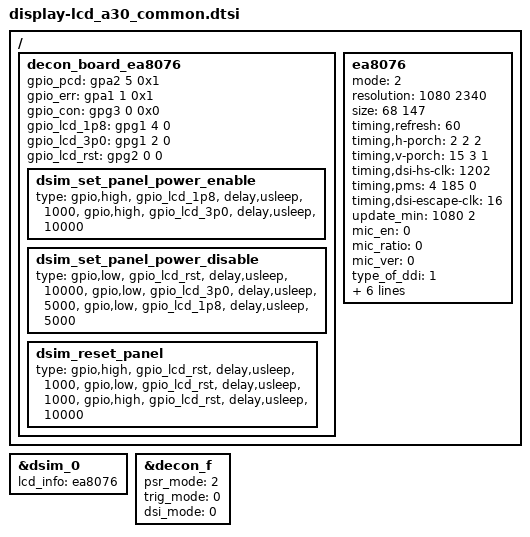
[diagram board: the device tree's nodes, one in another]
/*
 * SAMSUNG LCD Panel Device Tree Source
 *
 * Copyright (c) Samsung Electronics Co., Ltd.
 *		http://www.samsung.com
 *
 * This program is free software; you can redistribute it and/or modify
 * it under the terms of the GNU General Public License version 2 as
 * published by the Free Software Foundation.
 */

/ {
	fragment@lcd {
		target-path = "/";
		__overlay__ {
			decon_board_ea8076: decon_board_ea8076 {
				gpio_pcd = <&gpa2 5 0x1>;	/* EL_ON1_DET */
				gpio_err = <&gpa1 1 0x1>;	/* FG_ERR */
				gpio_con = <&gpg3 0 0x0>;	/* LCD_CON */

				gpio_lcd_1p8 = <&gpg1 4 0>;
				gpio_lcd_3p0 = <&gpg1 2 0>;
				gpio_lcd_rst = <&gpg2 0 0>;

				dsim_set_panel_power_enable {
					type =
					"gpio,high",	"gpio_lcd_1p8",
					"delay,usleep",	"1000",
					"gpio,high",	"gpio_lcd_3p0",
					"delay,usleep",	"10000";
				};
				dsim_set_panel_power_disable {
					type =
					"gpio,low",	"gpio_lcd_rst",
					"delay,usleep",	"10000",
					"gpio,low",	"gpio_lcd_3p0",
					"delay,usleep",	"5000",
					"gpio,low",	"gpio_lcd_1p8",
					"delay,usleep",	"5000";
				};
				dsim_reset_panel {
					type =
					"gpio,high",	"gpio_lcd_rst",
					"delay,usleep",	"1000",
					"gpio,low",	"gpio_lcd_rst",
					"delay,usleep",	"1000",
					"gpio,high",	"gpio_lcd_rst",
					"delay,usleep",	"10000";
				};
			};

			ea8076: ea8076 {
				mode = <2>; /* 0: video mode, 1: DP command mode, 2: MIPI command mode */
				resolution = <1080 2340>;
				size = <68 147>;	/* 67.932 * 147.186 */
				timing,refresh = <60>;
				/* HBP HFP HSW */
				timing,h-porch = <2 2 2>;
				/* VBP VFP VSW */
				timing,v-porch = <15 3 1>;
				timing,dsi-hs-clk = <1202>;
				timing,pms = <4 185 0>;
				timing,dsi-escape-clk = <16>;
				update_min = <1080 2>;
				mic_en = <0>;		/* 0: Disable, 1: Enable */
				mic_ratio = <0>;	/* 0: 1/2 mic, 1: 1/3 mic */
				mic_ver = <0>;		/* 0: mic v1.1, 1: v1.2, 2: v2.0 */
				type_of_ddi = <1>;	/* 0: Samsung Mobile, 1: MAGNA, 2: Normal(Etc) */
				dsc_en = <0>;		/* 0: Disable, 1: Enable */
				dsc_cnt = <0>;		/* used DSC count */
				dsc_slice_num = <0>;	/* count of dsc slice */
				data_lane = <4>;	/* number of using data lane */
				cmd_underrun_lp_ref = <5504>;	/* for underrun detect at command mode */
				decon_board = <&decon_board_ea8076>;
			};
		};
	};
};

&dsim_0 {
	lcd_info = <&ea8076>;
};

&decon_f {
	psr_mode = <2>;		/* 0: video mode, 1: DP command mode, 2: MIPI command mode */
	trig_mode = <0>;	/* 0: hw trigger, 1: sw trigger */
	dsi_mode = <0>;		/* 0: single dsi, 1: dual dsi */
};

